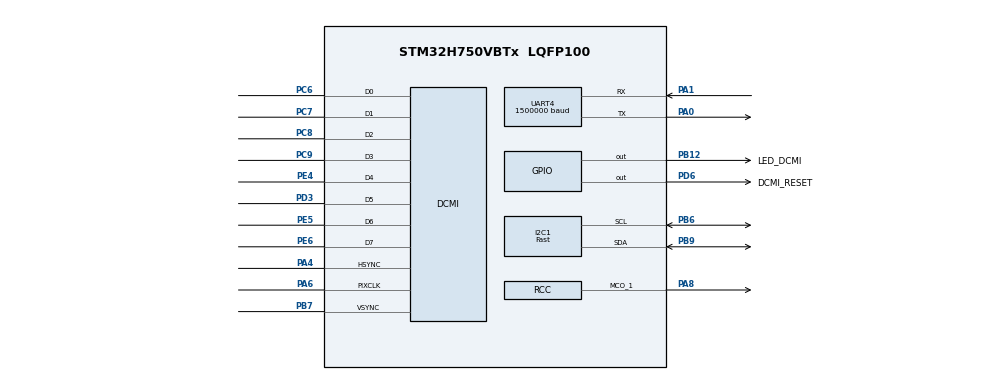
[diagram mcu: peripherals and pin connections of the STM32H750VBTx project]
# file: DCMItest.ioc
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DCMI.JPEGMode=DCMI_JPEG_ENABLE
DCMI.PCKPolarity=DCMI_PCKPOLARITY_RISING
Dma.DCMI.0.Direction=DMA_PERIPH_TO_MEMORY
Dma.DCMI.0.EventEnable=DISABLE
Dma.DCMI.0.FIFOMode=DMA_FIFOMODE_ENABLE
Dma.DCMI.0.FIFOThreshold=DMA_FIFO_THRESHOLD_FULL
Dma.DCMI.0.Instance=DMA1_Stream0
Dma.DCMI.0.MemBurst=DMA_MBURST_SINGLE
Dma.DCMI.0.MemDataAlignment=DMA_MDATAALIGN_WORD
Dma.DCMI.0.MemInc=DMA_MINC_ENABLE
Dma.DCMI.0.Mode=DMA_CIRCULAR
Dma.DCMI.0.PeriphBurst=DMA_PBURST_SINGLE
Dma.DCMI.0.PeriphDataAlignment=DMA_PDATAALIGN_WORD
Dma.DCMI.0.PeriphInc=DMA_PINC_DISABLE
Dma.DCMI.0.Polarity=HAL_DMAMUX_REQ_GEN_RISING
Dma.DCMI.0.Priority=DMA_PRIORITY_VERY_HIGH
Dma.DCMI.0.RequestNumber=1
Dma.DCMI.0.SignalID=NONE
Dma.DCMI.0.SyncEnable=DISABLE
Dma.DCMI.0.SyncPolarity=HAL_DMAMUX_SYNC_NO_EVENT
Dma.DCMI.0.SyncRequestNumber=1
Dma.DCMI.0.SyncSignalID=NONE
Dma.Request0=DCMI
I2C1.I2C_Speed_Mode=I2C_Fast
I2C1.Timing=0x009034B6
Mcu.Family=STM32H7
Mcu.Name=STM32H750VBTx
Mcu.Package=LQFP100
NVIC.DCMI_IRQn=true\:0\:0\:false\:false\:true\:true\:true
NVIC.DMA1_Stream0_IRQn=true\:0\:0\:false\:false\:true\:false\:true
NVIC.PriorityGroup=NVIC_PRIORITYGROUP_4
PA0.Mode=Asynchronous
PA0.Signal=UART4_TX
PA1.Mode=Asynchronous
PA1.Signal=UART4_RX
PA13\ (JTMS/SWDIO).Mode=Serial_Wire
PA13\ (JTMS/SWDIO).Signal=DEBUG_JTMS-SWDIO
PA14\ (JTCK/SWCLK).Mode=Serial_Wire
PA14\ (JTCK/SWCLK).Signal=DEBUG_JTCK-SWCLK
PA4.Mode=Slave_8_bits_External_Synchro
PA4.Signal=DCMI_HSYNC
PA6.Mode=Slave_8_bits_External_Synchro
PA6.Signal=DCMI_PIXCLK
PA8.Mode=Clock-out-1
PA8.Signal=RCC_MCO_1
PB12.GPIO_Label=LED_DCMI
PB12.PinState=GPIO_PIN_SET
PB12.Signal=GPIO_Output
PB6.Mode=I2C
PB6.Signal=I2C1_SCL
PB7.Mode=Slave_8_bits_External_Synchro
PB7.Signal=DCMI_VSYNC
PB9.Mode=I2C
PB9.Signal=I2C1_SDA
PC6.Mode=Slave_8_bits_External_Synchro
PC6.Signal=DCMI_D0
PC7.Mode=Slave_8_bits_External_Synchro
PC7.Signal=DCMI_D1
PC8.Mode=Slave_8_bits_External_Synchro
PC8.Signal=DCMI_D2
PC9.Mode=Slave_8_bits_External_Synchro
PC9.Signal=DCMI_D3
PD3.Mode=Slave_8_bits_External_Synchro
PD3.Signal=DCMI_D5
PD6.GPIO_Label=DCMI_RESET
PD6.PinState=GPIO_PIN_SET
PD6.Signal=GPIO_Output
PE4.Mode=Slave_8_bits_External_Synchro
PE4.Signal=DCMI_D4
PE5.Mode=Slave_8_bits_External_Synchro
PE5.Signal=DCMI_D6
PE6.Mode=Slave_8_bits_External_Synchro
PE6.Signal=DCMI_D7
PH0-OSC_IN\ (PH0).Mode=HSE-External-Oscillator
PH0-OSC_IN\ (PH0).Signal=RCC_OSC_IN
PH1-OSC_OUT\ (PH1).Mode=HSE-External-Oscillator
PH1-OSC_OUT\ (PH1).Signal=RCC_OSC_OUT
ProjectManager.HeapSize=0x200
ProjectManager.StackSize=0x400
ProjectManager.TargetToolchain=STM32CubeIDE
RCC.ADCFreq_Value=64500000
RCC.APB1Freq_Value=100000000
RCC.APB2Freq_Value=100000000
RCC.APB3Freq_Value=100000000
RCC.APB4Freq_Value=100000000
RCC.CortexFreq_Value=400000000
RCC.D1PPRE=RCC_APB3_DIV2
RCC.D2PPRE1=RCC_APB1_DIV2
RCC.D2PPRE2=RCC_APB2_DIV2
RCC.D3PPRE=RCC_APB4_DIV2
RCC.DIVM1=8
RCC.DIVN1=200
RCC.HCLKFreq_Value=200000000
RCC.HPRE=RCC_HCLK_DIV2
RCC.HSE_VALUE=32000000
RCC.PLLSourceVirtual=RCC_PLLSOURCE_HSE
RCC.RCC_MCODiv1=RCC_MCODIV_2
RCC.SYSCLKFreq_VALUE=400000000
RCC.SYSCLKSource=RCC_SYSCLKSOURCE_PLLCLK
RCC.USBFreq_Value=400000000
UART4.BaudRate=1500000
UART4.Parity=PARITY_NONE
board=custom

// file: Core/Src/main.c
/* USER CODE BEGIN Header */
/**
  ******************************************************************************
  * @file           : main.c
  * @brief          : Main program body
  ******************************************************************************
  * @attention
  *
  * <h2><center>&copy; Copyright (c) 2020 STMicroelectronics.
  * All rights reserved.</center></h2>
  *
  * This software component is licensed by ST under BSD 3-Clause license,
  * the "License"; You may not use this file except in compliance with the
  * License. You may obtain a copy of the License at:
  *                        opensource.org/licenses/BSD-3-Clause
  *
  ******************************************************************************
  */
/* USER CODE END Header */
#include "main.h"
#include "dcmi.h"
#include "dma.h"
#include "i2c.h"
#include "usart.h"
#include "gpio.h"

/* USER CODE BEGIN Includes */
#include "OV2640.h"

/* USER CODE END Includes */

/* USER CODE BEGIN PTD */
extern DCMI_HandleTypeDef hdcmi;
extern I2C_HandleTypeDef hi2c1;		//DCMI SCCB接口
extern I2C_HandleTypeDef hi2c2;		//JY61
extern UART_HandleTypeDef huart4;

/* USER CODE END PTD */

void SystemClock_Config(void);

int main(void)
{

  /* MCU Configuration--------------------------------------------------------*/

  /* Reset of all peripherals, Initializes the Flash interface and the Systick. */
  HAL_Init();

  /* Configure the system clock */
  SystemClock_Config();

  /* Initialize all configured peripherals */
  MX_GPIO_Init();
  MX_DMA_Init();
  MX_DCMI_Init();
  MX_UART4_Init();
  MX_I2C1_Init();
  /* USER CODE BEGIN 2 */
  HAL_GPIO_WritePin(DCMI_RESET_GPIO_Port, DCMI_RESET_Pin, GPIO_PIN_RESET);
  HAL_Delay(100);
  HAL_GPIO_WritePin(DCMI_RESET_GPIO_Port, DCMI_RESET_Pin, GPIO_PIN_SET);
  HAL_Delay(400);
  if(OV2640_Init(&hi2c1, &hdcmi, &huart4) == 0)
  {
	  HAL_GPIO_WritePin(LED_DCMI_GPIO_Port, LED_DCMI_Pin, GPIO_PIN_RESET);
  }
  HAL_Delay(2000);
  StartOV2640();
  /* USER CODE END 2 */

  /* Infinite loop */
  while (1)
  {

  }
}

void SystemClock_Config(void)
{
  RCC_OscInitTypeDef RCC_OscInitStruct = {0};
  RCC_ClkInitTypeDef RCC_ClkInitStruct = {0};
  RCC_PeriphCLKInitTypeDef PeriphClkInitStruct = {0};

  /** Supply configuration update enable
  */
  HAL_PWREx_ConfigSupply(PWR_LDO_SUPPLY);
  /** Configure the main internal regulator output voltage
  */
  __HAL_PWR_VOLTAGESCALING_CONFIG(PWR_REGULATOR_VOLTAGE_SCALE1);

  while(!__HAL_PWR_GET_FLAG(PWR_FLAG_VOSRDY)) {}
  /** Initializes the RCC Oscillators according to the specified parameters
  * in the RCC_OscInitTypeDef structure.
  */
  RCC_OscInitStruct.OscillatorType = RCC_OSCILLATORTYPE_HSI|RCC_OSCILLATORTYPE_HSE;
  RCC_OscInitStruct.HSEState = RCC_HSE_ON;
  RCC_OscInitStruct.HSIState = RCC_HSI_DIV1;
  RCC_OscInitStruct.HSICalibrationValue = RCC_HSICALIBRATION_DEFAULT;
  RCC_OscInitStruct.PLL.PLLState = RCC_PLL_ON;
  RCC_OscInitStruct.PLL.PLLSource = RCC_PLLSOURCE_HSE;
  RCC_OscInitStruct.PLL.PLLM = 8;
  RCC_OscInitStruct.PLL.PLLN = 200;
  RCC_OscInitStruct.PLL.PLLP = 2;
  RCC_OscInitStruct.PLL.PLLQ = 2;
  RCC_OscInitStruct.PLL.PLLR = 2;
  RCC_OscInitStruct.PLL.PLLRGE = RCC_PLL1VCIRANGE_2;
  RCC_OscInitStruct.PLL.PLLVCOSEL = RCC_PLL1VCOWIDE;
  RCC_OscInitStruct.PLL.PLLFRACN = 0;
  if (HAL_RCC_OscConfig(&RCC_OscInitStruct) != HAL_OK)
  {
    Error_Handler();
  }
  /** Initializes the CPU, AHB and APB buses clocks
  */
  RCC_ClkInitStruct.ClockType = RCC_CLOCKTYPE_HCLK|RCC_CLOCKTYPE_SYSCLK
                              |RCC_CLOCKTYPE_PCLK1|RCC_CLOCKTYPE_PCLK2
                              |RCC_CLOCKTYPE_D3PCLK1|RCC_CLOCKTYPE_D1PCLK1;
  RCC_ClkInitStruct.SYSCLKSource = RCC_SYSCLKSOURCE_PLLCLK;
  RCC_ClkInitStruct.SYSCLKDivider = RCC_SYSCLK_DIV1;
  RCC_ClkInitStruct.AHBCLKDivider = RCC_HCLK_DIV2;
  RCC_ClkInitStruct.APB3CLKDivider = RCC_APB3_DIV2;
  RCC_ClkInitStruct.APB1CLKDivider = RCC_APB1_DIV2;
  RCC_ClkInitStruct.APB2CLKDivider = RCC_APB2_DIV2;
  RCC_ClkInitStruct.APB4CLKDivider = RCC_APB4_DIV2;

  if (HAL_RCC_ClockConfig(&RCC_ClkInitStruct, FLASH_LATENCY_2) != HAL_OK)
  {
    Error_Handler();
  }
  PeriphClkInitStruct.PeriphClockSelection = RCC_PERIPHCLK_UART4|RCC_PERIPHCLK_I2C1;
  PeriphClkInitStruct.Usart234578ClockSelection = RCC_USART234578CLKSOURCE_D2PCLK1;
  PeriphClkInitStruct.I2c123ClockSelection = RCC_I2C123CLKSOURCE_D2PCLK1;
  if (HAL_RCCEx_PeriphCLKConfig(&PeriphClkInitStruct) != HAL_OK)
  {
    Error_Handler();
  }
  HAL_RCC_MCOConfig(RCC_MCO1, RCC_MCO1SOURCE_HSI, RCC_MCODIV_2);
}

void Error_Handler(void)
{
}

/************************ (C) COPYRIGHT STMicroelectronics *****END OF FILE****/
